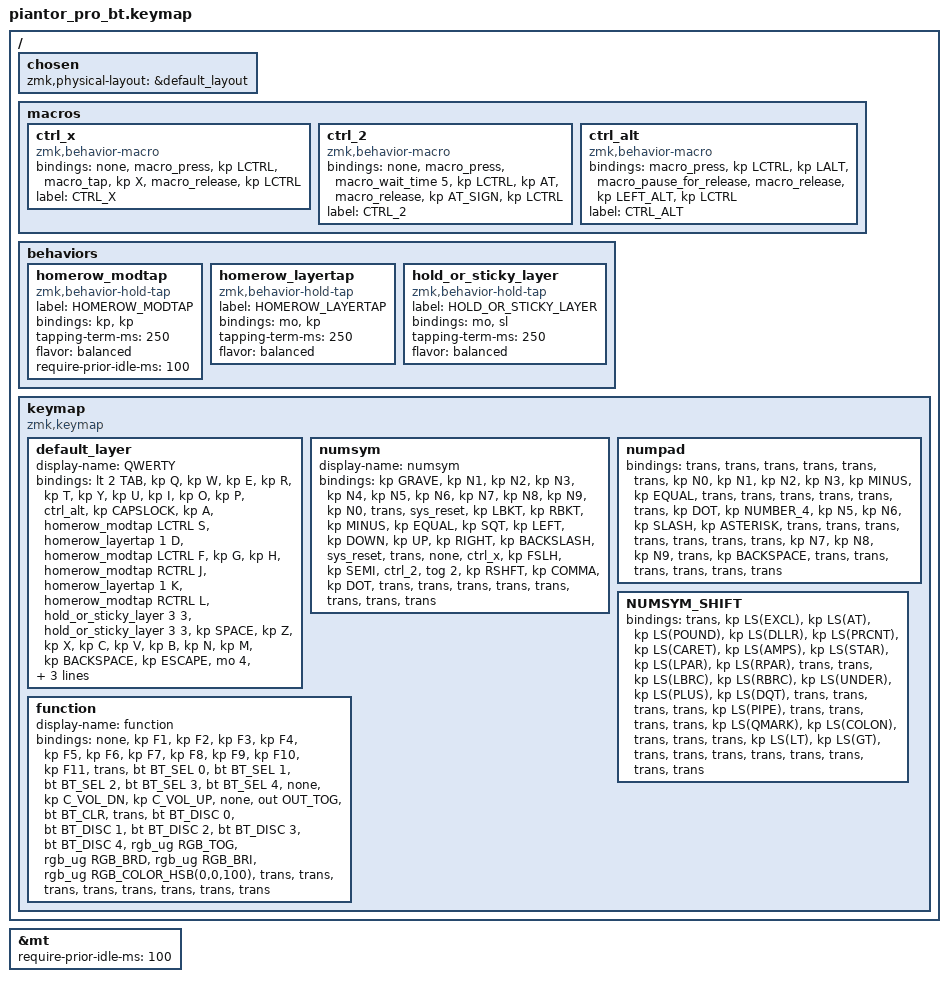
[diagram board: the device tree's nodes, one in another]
/*
 * Copyright (c) 2020 The ZMK Contributors
 *
 * SPDX-License-Identifier: MIT
 */

#include <behaviors.dtsi>
#include <dt-bindings/zmk/bt.h>
#include <dt-bindings/zmk/keys.h>
#include <dt-bindings/zmk/outputs.h>
#include <dt-bindings/zmk/rgb.h>

&mt { require-prior-idle-ms = <100>; };

/ {
    chosen { zmk,physical-layout = &default_layout; };
};

/ {
    macros {
        ctrl_x: ctrl_x {
            compatible = "zmk,behavior-macro";
            #binding-cells = <0>;
            bindings =
                <&none>,
                <&macro_press>,
                <&kp LCTRL>,
                <&macro_tap>,
                <&kp X>,
                <&macro_release>,
                <&kp LCTRL>;

            label = "CTRL_X";
        };

        ctrl_2: ctrl_2 {
            compatible = "zmk,behavior-macro";
            #binding-cells = <0>;
            bindings =
                <&none>,
                <&macro_press>,
                <&macro_wait_time 5>,
                <&kp LCTRL &kp AT>,
                <&macro_release>,
                <&kp AT_SIGN &kp LCTRL>;

            label = "CTRL_2";
        };

        ctrl_alt: ctrl_alt {
            compatible = "zmk,behavior-macro";
            #binding-cells = <0>;
            bindings =
                <&macro_press>,
                <&kp LCTRL &kp LALT>,
                <&macro_pause_for_release>,
                <&macro_release>,
                <&kp LEFT_ALT &kp LCTRL>;

            label = "CTRL_ALT";
        };
    };

    behaviors {
        homerow_modtap: homerow_modtap {
            compatible = "zmk,behavior-hold-tap";
            label = "HOMEROW_MODTAP";
            bindings = <&kp>, <&kp>;

            #binding-cells = <2>;
            tapping-term-ms = <250>;
            flavor = "balanced";
            require-prior-idle-ms = <100>;
        };

        homerow_layertap: homerow_layertap {
            compatible = "zmk,behavior-hold-tap";
            label = "HOMEROW_LAYERTAP";
            bindings = <&mo>, <&kp>;

            #binding-cells = <2>;
            tapping-term-ms = <250>;
            flavor = "balanced";
        };

        hold_or_sticky_layer: hold_or_sticky_layer {
            compatible = "zmk,behavior-hold-tap";
            label = "HOLD_OR_STICKY_LAYER";
            bindings = <&mo>, <&sl>;

            #binding-cells = <2>;
            tapping-term-ms = <250>;
            flavor = "balanced";
        };
    };

    keymap {
        compatible = "zmk,keymap";

        default_layer {
            display-name = "QWERTY";

            // --------------------------------------------------------------------------------
            // |  TAB |  Q  |  W  |  E  |  R  |  T  |  Y  |  U   |  I  |  O  |  P  | BSPC |
            // | CTRL |  A  |  S  |  D  |  F  |  G  |  H  |  J   |  K  |  L  |  ;  |  '   |
            // | SHFT |  Z  |  X  |  C  |  V  |  B  |  N  |  M   |  ,  |  .  |  /  | ESC  |
            //                    | GUI | LWR | SPC | ENT | RSE  | ALT |

            bindings = <
&lt 2 TAB  &kp Q  &kp W  &kp E  &kp R  &kp T  &kp Y  &kp U  &kp I  &kp O  &kp P  &ctrl_alt  &kp CAPSLOCK  &kp A  &homerow_modtap LCTRL S  &homerow_layertap 1 D  &homerow_modtap LCTRL F  &kp G  &kp H  &homerow_modtap RCTRL J  &homerow_layertap 1 K  &homerow_modtap RCTRL L  &hold_or_sticky_layer 3 3  &hold_or_sticky_layer 3 3  &kp SPACE  &kp Z  &kp X  &kp C  &kp V  &kp B  &kp N  &kp M  &kp BACKSPACE  &kp ESCAPE  &mo 4  &hold_or_sticky_layer 3 3  &kp LGUI  &mt LEFT_ALT SPACE  &mt LSHFT RET  &mt LCTRL RET  &mo 1  &mo 1
            >;
        };

        numsym {
            display-name = "numsym";

            // -----------------------------------------------------------------------------------------
            // |  TAB |  1  |  2  |  3  |  4  |  5    |  6  |  7  |  8  |  9  |  0  | BSPC |
            // | CTRL | BT1 | BT2 | BT3 | BT4 | BT5   | LFT | DWN |  UP | RGT |     |      |
            // | SHFT | BTCR| RGB | RST | BOOT| Unlock|     |     |     |     |     |      |
            //                    | GUI |     | SPC   | ENT |     | ALT |

            bindings = <
&kp GRAVE  &kp N1  &kp N2  &kp N3  &kp N4  &kp N5  &kp N6  &kp N7  &kp N8  &kp N9  &kp N0  &trans  &sys_reset  &kp LBKT  &kp RBKT  &kp MINUS  &kp EQUAL  &kp SQT  &kp LEFT  &kp DOWN  &kp UP  &kp RIGHT  &kp BACKSLASH  &sys_reset  &trans  &none  &ctrl_x  &kp FSLH  &kp SEMI  &ctrl_2  &tog 2  &kp RSHFT  &kp COMMA  &kp DOT  &trans  &trans  &trans  &trans  &trans  &trans  &trans  &trans
            >;
        };

        numpad {
            bindings = <
&trans  &trans  &trans  &trans  &trans  &trans  &kp N0  &kp N1  &kp N2  &kp N3  &kp MINUS  &kp EQUAL  &trans  &trans  &trans  &trans  &trans  &trans  &kp DOT  &kp NUMBER_4  &kp N5  &kp N6  &kp SLASH  &kp ASTERISK  &trans  &trans  &trans  &trans  &trans  &trans  &trans  &kp N7  &kp N8  &kp N9  &trans  &kp BACKSPACE  &trans  &trans  &trans  &trans  &trans  &trans
            >;
        };

        NUMSYM_SHIFT {
            bindings = <
&trans  &kp LS(EXCL)  &kp LS(AT)  &kp LS(POUND)  &kp LS(DLLR)  &kp LS(PRCNT)  &kp LS(CARET)  &kp LS(AMPS)  &kp LS(STAR)  &kp LS(LPAR)  &kp LS(RPAR)  &trans  &trans  &kp LS(LBRC)  &kp LS(RBRC)  &kp LS(UNDER)  &kp LS(PLUS)  &kp LS(DQT)  &trans  &trans  &trans  &trans  &kp LS(PIPE)  &trans  &trans  &trans  &trans  &kp LS(QMARK)  &kp LS(COLON)  &trans  &trans  &trans  &kp LS(LT)  &kp LS(GT)  &trans  &trans  &trans  &trans  &trans  &trans  &trans  &trans
            >;
        };

        function {
            display-name = "function";
            bindings = <
&none  &kp F1  &kp F2  &kp F3  &kp F4  &kp F5  &kp F6  &kp F7  &kp F8  &kp F9  &kp F10  &kp F11  &trans  &bt BT_SEL 0  &bt BT_SEL 1  &bt BT_SEL 2  &bt BT_SEL 3  &bt BT_SEL 4  &none  &kp C_VOL_DN  &kp C_VOL_UP  &none  &out OUT_TOG  &bt BT_CLR  &trans  &bt BT_DISC 0  &bt BT_DISC 1  &bt BT_DISC 2  &bt BT_DISC 3  &bt BT_DISC 4  &rgb_ug RGB_TOG  &rgb_ug RGB_BRD  &rgb_ug RGB_BRI  &rgb_ug RGB_COLOR_HSB(0,0,100)  &trans  &trans  &trans  &trans  &trans  &trans  &trans  &trans
            >;
        };
    };
};
